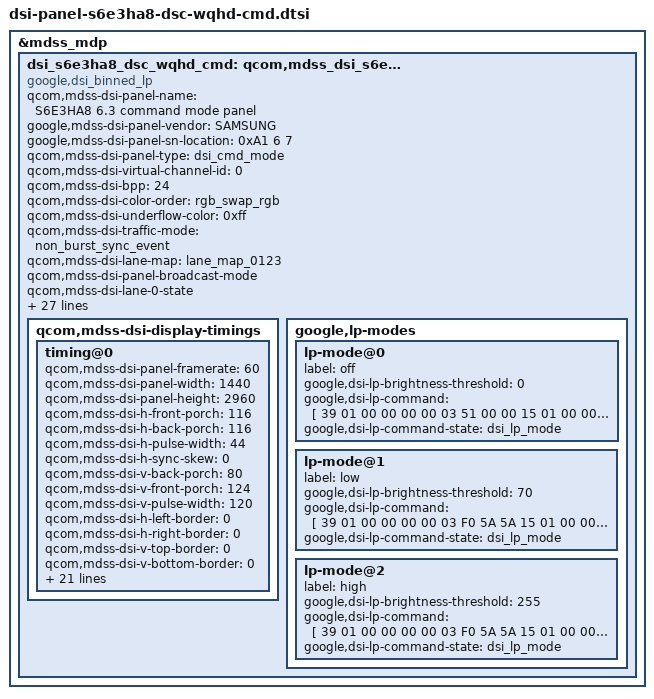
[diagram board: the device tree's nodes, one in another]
/* Copyright (c) 2017, The Linux Foundation. All rights reserved.
 *
 * This program is free software; you can redistribute it and/or modify
 * it under the terms of the GNU General Public License version 2 and
 * only version 2 as published by the Free Software Foundation.
 *
 * This program is distributed in the hope that it will be useful,
 * but WITHOUT ANY WARRANTY; without even the implied warranty of
 * MERCHANTABILITY or FITNESS FOR A PARTICULAR PURPOSE.  See the
 * GNU General Public License for more details.
 */

&mdss_mdp {
	dsi_s6e3ha8_dsc_wqhd_cmd: qcom,mdss_dsi_s6e3ha8 {
		compatible = "google,dsi_binned_lp";

		qcom,mdss-dsi-panel-name = "S6E3HA8 6.3 command mode panel";
		google,mdss-dsi-panel-vendor = "SAMSUNG";
		google,mdss-dsi-panel-sn-location = <0xA1 6 7>;
		qcom,mdss-dsi-panel-type = "dsi_cmd_mode";
		qcom,mdss-dsi-virtual-channel-id = <0>;
		qcom,mdss-dsi-bpp = <24>;
		qcom,mdss-dsi-color-order = "rgb_swap_rgb";
		qcom,mdss-dsi-underflow-color = <0xff>;
		qcom,mdss-dsi-traffic-mode = "non_burst_sync_event";
		qcom,mdss-dsi-lane-map = "lane_map_0123";
		qcom,mdss-dsi-panel-broadcast-mode;
		qcom,mdss-dsi-lane-0-state;
		qcom,mdss-dsi-lane-1-state;
		qcom,mdss-dsi-lane-2-state;
		qcom,mdss-dsi-lane-3-state;
		qcom,mdss-dsi-reset-sequence = <1 10>, <0 1>, <1 0>;

		qcom,mdss-dsi-bl-pmic-control-type = "bl_ctrl_dcs";
		qcom,mdss-dsi-panel-hdr-enabled;
		qcom,mdss-dsi-panel-hdr-color-primaries = <14500 15500 32000
			17000 15500 30000 8000 3000>;
		qcom,mdss-dsi-panel-peak-brightness = <5530000>;
		qcom,mdss-dsi-panel-blackness-level = <40>;

		qcom,mdss-dsi-dma-trigger = "trigger_sw";
		qcom,mdss-dsi-mdp-trigger = "none";
		qcom,mdss-dsi-wr-mem-start = <0x2c>;
		qcom,mdss-dsi-wr-mem-continue = <0x3c>;
		qcom,mdss-dsi-te-pin-select = <1>;
		qcom,mdss-dsi-te-dcs-command = <1>;

		qcom,mdss-dsi-te-check-enable;
		qcom,mdss-dsi-te-using-te-pin;
		/* qcom,esd-check-enabled; */
		qcom,mdss-dsi-panel-status-check-mode = "te_signal_check";

		qcom,mdss-dsi-init-delay-us = <5000>;

		qcom,mdss-pan-physical-width-dimension  = <73>;
		qcom,mdss-pan-physical-height-dimension = <154>;

		qcom,mdss-brightness-max-level = <255>;
		/* Minimum brightness corresponds to ~2 nits.
		   >= 0x0a for PMIC safety in VR mode. */
		qcom,mdss-dsi-bl-lut = <
			0x0   0x5d  0x71  0x83  0x95  0xa6  0xb6  0xc1
			0xcb  0xd5  0xde  0xe8  0xf1  0xfb  0x105 0x10e
			0x117 0x11e 0x125 0x12c 0x132 0x139 0x140 0x147
			0x14d 0x154 0x15b 0x162 0x169 0x16f 0x175 0x17b
			0x180 0x185 0x18a 0x190 0x195 0x19a 0x19f 0x1a5
			0x1aa 0x1b0 0x1b6 0x1bb 0x1c1 0x1c6 0x1cc 0x1d1
			0x1d5 0x1da 0x1de 0x1e3 0x1e7 0x1ec 0x1f1 0x1f5
			0x1fa 0x1fe 0x203 0x208 0x20c 0x211 0x216 0x21b
			0x220 0x225 0x22a 0x22f 0x233 0x237 0x23b 0x23f
			0x242 0x246 0x249 0x24c 0x24f 0x252 0x255 0x258
			0x25c 0x25f 0x263 0x266 0x269 0x26d 0x270 0x273
			0x275 0x278 0x27b 0x27d 0x280 0x283 0x286 0x289
			0x28d 0x290 0x293 0x296 0x299 0x29c 0x29f 0x2a1
			0x2a4 0x2a7 0x2aa 0x2ac 0x2af 0x2b1 0x2b3 0x2b6
			0x2b8 0x2bb 0x2bd 0x2c0 0x2c3 0x2c6 0x2c9 0x2cb
			0x2ce 0x2d1 0x2d4 0x2d6 0x2d8 0x2da 0x2dc 0x2de
			0x2e0 0x2e2 0x2e5 0x2e7 0x2ea 0x2ee 0x2f1 0x2f4
			0x2f8 0x2fb 0x2fd 0x300 0x302 0x305 0x307 0x30a
			0x30c 0x30f 0x311 0x313 0x316 0x318 0x31a 0x31c
			0x31f 0x321 0x323 0x326 0x328 0x32a 0x32d 0x32f
			0x332 0x334 0x336 0x339 0x33c 0x33e 0x341 0x344
			0x347 0x349 0x34c 0x34e 0x350 0x352 0x354 0x356
			0x358 0x35b 0x35d 0x35f 0x361 0x363 0x365 0x367
			0x36a 0x36c 0x36e 0x370 0x372 0x375 0x377 0x37a
			0x37c 0x37f 0x382 0x384 0x387 0x389 0x38b 0x38d
			0x38f 0x391 0x393 0x395 0x397 0x399 0x39b 0x39d
			0x39f 0x3a1 0x3a3 0x3a5 0x3a7 0x3a8 0x3aa 0x3ac
			0x3ae 0x3b0 0x3b3 0x3b5 0x3b7 0x3ba 0x3bc 0x3be
			0x3c0 0x3c3 0x3c5 0x3c7 0x3c9 0x3cb 0x3cd 0x3cf
			0x3d0 0x3d2 0x3d4 0x3d6 0x3d8 0x3da 0x3dc 0x3de
			0x3df 0x3e1 0x3e3 0x3e5 0x3e6 0x3e8 0x3ea 0x3ec
			0x3ee 0x3f1 0x3f3 0x3f5 0x3f8 0x3fa 0x3fd 0x3ff
		>;

		qcom,mdss-dsi-display-timings {
			timing@0 {
				qcom,mdss-dsi-panel-framerate = <60>;
				qcom,mdss-dsi-panel-width = <1440>;
				qcom,mdss-dsi-panel-height = <2960>;
				qcom,mdss-dsi-h-front-porch = <116>;
				qcom,mdss-dsi-h-back-porch = <116>;
				qcom,mdss-dsi-h-pulse-width = <44>;
				qcom,mdss-dsi-h-sync-skew = <0>;
				qcom,mdss-dsi-v-back-porch = <80>;
				qcom,mdss-dsi-v-front-porch = <124>;
				qcom,mdss-dsi-v-pulse-width = <120>;
				qcom,mdss-dsi-h-left-border = <0>;
				qcom,mdss-dsi-h-right-border = <0>;
				qcom,mdss-dsi-v-top-border = <0>;
				qcom,mdss-dsi-v-bottom-border = <0>;
				qcom,mdss-dsi-on-command = [
					07 01 00 00 00 00 01 01    /* Compression Enable */
					05 01 00 00 78 00 01 11    /* sleep out, Wait 120 ms */
					15 01 00 00 00 00 02 53 20 /* Write Control Display */
					05 01 00 00 00 00 02 35 00 /* TE on */
					39 01 00 00 00 00 03 F0 5A 5A /* Unlock */
					39 01 00 00 00 00 0A B9 01 B0 81 09 00 00 00 11 03 /* Sync display with touch */
					39 01 00 00 00 00 03 F0 A5 A5 /* Lock */
					05 01 00 00 00 00 01 29    /* display on */
				];
				qcom,mdss-dsi-on-command-state = "dsi_lp_mode";
				qcom,mdss-dsi-off-command = [
					05 01 00 00 0A 00 02 28 00 /* display off */
					05 01 00 00 78 00 02 10 00 /* sleep in */
				];

				qcom,mdss-dsi-vr-command = [
					39 01 00 00 00 00 03 F0 5A 5A
					15 01 00 00 00 00 02 B8 11
					39 01 00 00 00 00 05 B1 02 54 0C 00
					15 01 00 00 00 00 02 B0 10
					39 01 00 00 00 00 03 CB 03 0E
					15 01 00 00 00 00 02 B0 25
					15 01 00 00 00 00 02 CB 15
					15 01 00 00 00 00 02 B0 43
					15 01 00 00 00 00 02 CB 8F
					15 01 00 00 00 00 02 F7 03
					15 01 00 00 00 00 02 B0 08
					15 01 00 00 00 00 02 B1 50
					39 01 00 00 00 00 03 F0 A5 A5
					39 01 00 00 00 00 03 51 00 BB
				];

				qcom,mdss-dsi-novr-command = [
					39 01 00 00 00 00 03 F0 5A 5A
					15 01 00 00 00 00 02 B0 08
					15 01 00 00 00 00 02 B1 2D
					15 01 00 00 00 00 02 B0 10
					39 01 00 00 00 00 03 CB 0B 06
					15 01 00 00 00 00 02 B0 25
					15 01 00 00 00 00 02 CB 09
					15 01 00 00 00 00 02 B0 43
					15 01 00 00 00 00 02 CB 0F
					39 01 00 00 00 00 03 B1 00 0C
					15 01 00 00 00 00 02 F7 03
					39 01 00 00 00 00 03 F0 A5 A5
				];
				qcom,mdss-dsi-off-command-state = "dsi_hs_mode";

				qcom,mdss-dsi-nolp-command = [
					15 01 00 00 00 00 02 53 20
				];

				qcom,compression-mode = "dsc";
				qcom,mdss-dsc-slice-height = <40>;
				qcom,mdss-dsc-slice-width = <720>;
				qcom,mdss-dsc-slice-per-pkt = <1>;
				qcom,mdss-dsc-bit-per-component = <8>;
				qcom,mdss-dsc-bit-per-pixel = <8>;
				qcom,mdss-dsc-block-prediction-enable;

				/* 2xLM, 2xDSC Enc, 1xDSI Intf */
				qcom,display-topology = <2 2 1>;
				qcom,default-topology-index = <0>;
			};
		};

		google,lp-modes {
			lp-mode@0 {
				label = "off";

				google,dsi-lp-brightness-threshold = <0>;
				google,dsi-lp-command = [
					39 01 00 00 00 00 03 51 00 00 /* turn screen dark */
					15 01 00 00 00 00 02 53 20    /* disable HLPM */
				];
				google,dsi-lp-command-state = "dsi_lp_mode";
			};

			lp-mode@1 {
				label = "low";

				google,dsi-lp-brightness-threshold = <70>;
				google,dsi-lp-command = [
					39 01 00 00 00 00 03 F0 5A 5A /* Unlock */
					15 01 00 00 00 00 02 B0 05
					15 01 00 00 00 00 02 BB 84
					15 01 00 00 00 00 02 53 03
					15 01 00 00 00 00 02 F7 03
					39 01 00 00 00 00 03 F0 A5 A5 /* Lock */
				];
				google,dsi-lp-command-state = "dsi_lp_mode";
			};

			lp-mode@2 {
				label = "high";
				google,dsi-lp-brightness-threshold = <255>;
				google,dsi-lp-command = [
					39 01 00 00 00 00 03 F0 5A 5A /* Unlock */
					15 01 00 00 00 00 02 B0 05
					15 01 00 00 00 00 02 BB 04
					15 01 00 00 00 00 02 53 02
					15 01 00 00 00 00 02 F7 03
					39 01 00 00 00 00 03 F0 A5 A5 /* Lock */
				];
				google,dsi-lp-command-state = "dsi_lp_mode";
			};
		};
	};
};
